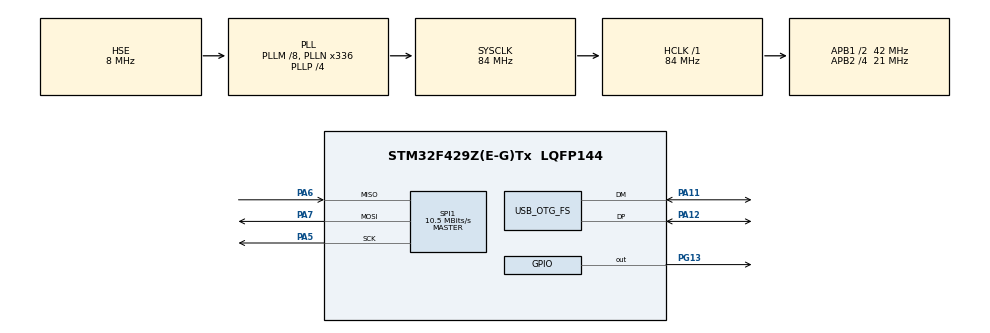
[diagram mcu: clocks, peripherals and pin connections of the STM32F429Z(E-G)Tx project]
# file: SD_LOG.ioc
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FATFS._MAX_SS=4096
FATFS._USE_LFN=1
Mcu.Family=STM32F4
Mcu.Name=STM32F429Z(E-G)Tx
Mcu.Package=LQFP144
NVIC.OTG_FS_IRQn=true\:0\:0\:false\:false\:true\:false\:true\:true
NVIC.PriorityGroup=NVIC_PRIORITYGROUP_4
PA11.Mode=Device_Only
PA11.Signal=USB_OTG_FS_DM
PA12.Mode=Device_Only
PA12.Signal=USB_OTG_FS_DP
PA5.Mode=Full_Duplex_Master
PA5.Signal=SPI1_SCK
PA6.Mode=Full_Duplex_Master
PA6.Signal=SPI1_MISO
PA7.Mode=Full_Duplex_Master
PA7.Signal=SPI1_MOSI
PG13.Signal=GPIO_Output
PH0/OSC_IN.Mode=HSE-External-Oscillator
PH0/OSC_IN.Signal=RCC_OSC_IN
PH1/OSC_OUT.Mode=HSE-External-Oscillator
PH1/OSC_OUT.Signal=RCC_OSC_OUT
ProjectManager.HeapSize=0x200
ProjectManager.StackSize=0x400
ProjectManager.TargetToolchain=STM32CubeIDE
RCC.48MHZClocksFreq_Value=48000000
RCC.AHBFreq_Value=84000000
RCC.APB1CLKDivider=RCC_HCLK_DIV2
RCC.APB1Freq_Value=42000000
RCC.APB1TimFreq_Value=84000000
RCC.APB2CLKDivider=RCC_HCLK_DIV4
RCC.APB2Freq_Value=21000000
RCC.APB2TimFreq_Value=42000000
RCC.CortexFreq_Value=84000000
RCC.HCLKFreq_Value=84000000
RCC.HSE_VALUE=8000000
RCC.HSI_VALUE=16000000
RCC.LSE_VALUE=32768
RCC.PLLM=8
RCC.PLLN=336
RCC.PLLP=RCC_PLLP_DIV4
RCC.PLLQ=7
RCC.SYSCLKFreq_VALUE=84000000
RCC.SYSCLKSource=RCC_SYSCLKSOURCE_PLLCLK
RCC.VCOOutputFreq_Value=336000000
SPI1.CalculateBaudRate=10.5 MBits/s
SPI1.Direction=SPI_DIRECTION_2LINES
SPI1.Mode=SPI_MODE_MASTER
SPI1.VirtualType=VM_MASTER
USB_DEVICE.CLASS_NAME_FS=CDC
USB_DEVICE.VirtualMode-CDC_FS=Cdc
USB_DEVICE.VirtualModeFS=Cdc_FS
USB_OTG_FS.VirtualMode=Device_Only
VP_FATFS_VS_Generic.Mode=User_defined
VP_USB_DEVICE_VS_USB_DEVICE_CDC_FS.Mode=CDC_FS
board=custom

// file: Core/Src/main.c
/* USER CODE BEGIN Header */
/**
  ******************************************************************************
  * @file           : main.c
  * @brief          : Main program body
  ******************************************************************************
  * @attention
  *
  * Copyright (c) 2025 STMicroelectronics.
  * All rights reserved.
  *
  * This software is licensed under terms that can be found in the LICENSE file
  * in the root directory of this software component.
  * If no LICENSE file comes with this software, it is provided AS-IS.
  *
  ******************************************************************************
  */
/* USER CODE END Header */
#include "main.h"
#include "fatfs.h"
#include "usb_device.h"

/* USER CODE BEGIN Includes */
#include <stdbool.h>
#include <stdio.h>
#include <string.h>
/* USER CODE END Includes */

/* USER CODE BEGIN PV */
SPI_HandleTypeDef hspi1;
char TxBuffer[250];
/* USER CODE END PV */

void SystemClock_Config(void);
static void MX_GPIO_Init(void);
static void MX_SPI1_Init(void);
/* USER CODE BEGIN PFP */
void MX_USB_DEVICE_Init(void);  // ✅ ADDED: USB Device initialization
static void SD_Card_Test(void);
/* USER CODE END PFP */

/* USER CODE BEGIN 0 */
static void USB_CDC_Print(char* str)
{
    CDC_Transmit_FS((uint8_t*)str, strlen(str));  // Send via USB CDC
    HAL_Delay(10);  // Small delay to ensure transmission completes
}
/* USER CODE END 0 */

int main(void)
{

  /* MCU Configuration--------------------------------------------------------*/

  /* Reset of all peripherals, Initializes the Flash interface and the Systick. */
  HAL_Init();

  /* Configure the system clock */
  SystemClock_Config();

  /* Initialize all configured peripherals */
  MX_GPIO_Init();
  MX_USB_DEVICE_Init();
  MX_SPI1_Init();

  /* USER CODE BEGIN 2 */
  MX_FATFS_Init();
  HAL_Delay(2000);  // ✅ ADDED: Wait for USB enumeration to complete
  USB_CDC_Print("\r\n=== STM32F429 SD Card Test via USB CDC ===\r\n\n");  // ✅ CHANGED
  SD_Card_Test();
  /* USER CODE END 2 */

  /* Infinite loop */
  while (1)
  {

  }
}

static void SD_Card_Test(void)
{
  FATFS FatFs;
  FIL Fil;
  FRESULT FR_Status;
  FATFS *FS_Ptr;
  UINT RWC, WWC; // Read/Write Word Counter
  DWORD FreeClusters;
  uint32_t TotalSize, FreeSpace;
  char RW_Buffer[200];

  do
  {
    //------------------[ Mount The SD Card ]--------------------
    FR_Status = f_mount(&FatFs, "", 1);
    if (FR_Status != FR_OK)
    {
      sprintf(TxBuffer, "Error! While Mounting SD Card, Error Code: (%i)\r\n", FR_Status);
      USB_CDC_Print(TxBuffer);  // ✅ CHANGED: UART_Print → USB_CDC_Print
      break;
    }
    sprintf(TxBuffer, "SD Card Mounted Successfully! \r\n\n");
    USB_CDC_Print(TxBuffer);  // ✅ CHANGED

    //------------------[ Get & Print The SD Card Size & Free Space ]--------------------
    f_getfree("", &FreeClusters, &FS_Ptr);
    TotalSize = (uint32_t)((FS_Ptr->n_fatent - 2) * FS_Ptr->csize * 0.5);
    FreeSpace = (uint32_t)(FreeClusters * FS_Ptr->csize * 0.5);
    sprintf(TxBuffer, "Total SD Card Size: %lu Bytes\r\n", TotalSize);
    USB_CDC_Print(TxBuffer);  // ✅ CHANGED
    sprintf(TxBuffer, "Free SD Card Space: %lu Bytes\r\n\n", FreeSpace);
    USB_CDC_Print(TxBuffer);  // ✅ CHANGED

    //------------------[ Open A Text File For Write & Write Data ]--------------------
    //Open the file
    FR_Status = f_open(&Fil, "TextFileWrite.txt", FA_WRITE | FA_READ | FA_CREATE_ALWAYS);
    if(FR_Status != FR_OK)
    {
      sprintf(TxBuffer, "Error! While Creating/Opening A New Text File, Error Code: (%i)\r\n", FR_Status);
      USB_CDC_Print(TxBuffer);  // ✅ CHANGED
      break;
    }
    sprintf(TxBuffer, "Text File Created & Opened! Writing Data To The Text File..\r\n\n");
    USB_CDC_Print(TxBuffer);

    // (1) Write Data To The Text File [ Using f_puts() Function ]
    f_puts("Hello! From STM32F429 To SD Card Over SPI1, Using f_puts()\n", &Fil);
    strcpy(RW_Buffer, "Hello! From STM32F429 To SD Card Over SPI1, Using f_write()\r\n");
    f_write(&Fil, RW_Buffer, strlen(RW_Buffer), &WWC);
    // Close The File
    f_close(&Fil);

    //------------------[ Open A Text File For Read & Read Its Data ]--------------------
    // Open The File
    FR_Status = f_open(&Fil, "TextFileWrite.txt", FA_READ);
    if(FR_Status != FR_OK)
    {
      sprintf(TxBuffer, "Error! While Opening (TextFileWrite.txt) File For Read.. \r\n");
      USB_CDC_Print(TxBuffer);  // ✅ CHANGED
      break;
    }

    // (1) Read The Text File's Data [ Using f_gets() Function ]
    f_gets(RW_Buffer, sizeof(RW_Buffer), &Fil);
    sprintf(TxBuffer, "Data Read From (TextFileWrite.txt) Using f_gets():%s", RW_Buffer);
    USB_CDC_Print(TxBuffer);  // ✅ CHANGED

    // (2) Read The Text File's Data [ Using f_read() Function ]
    f_read(&Fil, RW_Buffer, f_size(&Fil), &RWC);
    sprintf(TxBuffer, "Data Read From (TextFileWrite.txt) Using f_read():%s", RW_Buffer);
    USB_CDC_Print(TxBuffer);  // ✅ CHANGED

    // Close The File
    f_close(&Fil);
    sprintf(TxBuffer, "File Closed! \r\n\n");
    USB_CDC_Print(TxBuffer);  // ✅ CHANGED

    //------------------[ Open An Existing Text File, Update Its Content, Read It Back ]--------------------
    // (1) Open The Existing File For Write (Update)
    FR_Status = f_open(&Fil, "TextFileWrite.txt", FA_OPEN_EXISTING | FA_WRITE);
    FR_Status = f_lseek(&Fil, f_size(&Fil)); // Move The File Pointer To The EOF (End-Of-File)
    if(FR_Status != FR_OK)
    {
      sprintf(TxBuffer, "Error! While Opening (TextFileWrite.txt) File For Update.. \r\n");
      USB_CDC_Print(TxBuffer);  // ✅ CHANGED
      break;
    }

    // (2) Write New Line of Text Data To The File
    FR_Status = f_puts("This New Line Was Added During Update!\r\n", &Fil);
    f_close(&Fil);
    memset(RW_Buffer,'\0',sizeof(RW_Buffer)); // Clear The Buffer

    // (3) Read The Contents of The Text File After The Update
    FR_Status = f_open(&Fil, "TextFileWrite.txt", FA_READ); // Open The File For Read
    f_read(&Fil, RW_Buffer, f_size(&Fil), &RWC);
    sprintf(TxBuffer, "Data Read From (TextFileWrite.txt) After Update:%s", RW_Buffer);
    USB_CDC_Print(TxBuffer);  // ✅ CHANGED
    f_close(&Fil);

    //------------------[ Delete The Text File ]--------------------
    // Delete The File
    /*
    FR_Status = f_unlink("TextFileWrite.txt");
    if (FR_Status != FR_OK){
        sprintf(TxBuffer, "Error! While Deleting The (TextFileWrite.txt) File.. \r\n");
        USB_CDC_Print(TxBuffer);
    }
    */
  } while(0);

  //------------------[ Test Complete! Unmount The SD Card ]--------------------
  FR_Status = f_mount(NULL, "", 0);
  if (FR_Status != FR_OK)
  {
      sprintf(TxBuffer, "Error! While Un-mounting SD Card, Error Code: (%i)\r\n", FR_Status);
      USB_CDC_Print(TxBuffer);  // ✅ CHANGED
  } else {
      sprintf(TxBuffer, "SD Card Un-mounted Successfully! \r\n");
      USB_CDC_Print(TxBuffer);  // ✅ CHANGED
  }
}

void SystemClock_Config(void)
{
  RCC_OscInitTypeDef RCC_OscInitStruct = {0};
  RCC_ClkInitTypeDef RCC_ClkInitStruct = {0};

  /** Configure the main internal regulator output voltage
  */
  __HAL_RCC_PWR_CLK_ENABLE();
  __HAL_PWR_VOLTAGESCALING_CONFIG(PWR_REGULATOR_VOLTAGE_SCALE3);

  /** Initializes the RCC Oscillators according to the specified parameters
  * in the RCC_OscInitTypeDef structure.
  */
  RCC_OscInitStruct.OscillatorType = RCC_OSCILLATORTYPE_HSE;
  RCC_OscInitStruct.HSEState = RCC_HSE_ON;
  RCC_OscInitStruct.PLL.PLLState = RCC_PLL_ON;
  RCC_OscInitStruct.PLL.PLLSource = RCC_PLLSOURCE_HSE;
  RCC_OscInitStruct.PLL.PLLM = 8;
  RCC_OscInitStruct.PLL.PLLN = 336;
  RCC_OscInitStruct.PLL.PLLP = RCC_PLLP_DIV4;
  RCC_OscInitStruct.PLL.PLLQ = 7;
  if (HAL_RCC_OscConfig(&RCC_OscInitStruct) != HAL_OK)
  {
    Error_Handler();
  }

  /** Initializes the CPU, AHB and APB buses clocks
  */
  RCC_ClkInitStruct.ClockType = RCC_CLOCKTYPE_HCLK|RCC_CLOCKTYPE_SYSCLK
                              |RCC_CLOCKTYPE_PCLK1|RCC_CLOCKTYPE_PCLK2;
  RCC_ClkInitStruct.SYSCLKSource = RCC_SYSCLKSOURCE_PLLCLK;
  RCC_ClkInitStruct.AHBCLKDivider = RCC_SYSCLK_DIV1;
  RCC_ClkInitStruct.APB1CLKDivider = RCC_HCLK_DIV2;
  RCC_ClkInitStruct.APB2CLKDivider = RCC_HCLK_DIV4;

  if (HAL_RCC_ClockConfig(&RCC_ClkInitStruct, FLASH_LATENCY_2) != HAL_OK)
  {
    Error_Handler();
  }
}

static void MX_SPI1_Init(void)
{

  /* SPI1 parameter configuration*/
  hspi1.Instance = SPI1;
  hspi1.Init.Mode = SPI_MODE_MASTER;
  hspi1.Init.Direction = SPI_DIRECTION_2LINES;
  hspi1.Init.DataSize = SPI_DATASIZE_8BIT;
  hspi1.Init.CLKPolarity = SPI_POLARITY_LOW;
  hspi1.Init.CLKPhase = SPI_PHASE_1EDGE;
  hspi1.Init.NSS = SPI_NSS_SOFT;
  hspi1.Init.BaudRatePrescaler = SPI_BAUDRATEPRESCALER_256;
  hspi1.Init.FirstBit = SPI_FIRSTBIT_MSB;
  hspi1.Init.TIMode = SPI_TIMODE_DISABLE;
  hspi1.Init.CRCCalculation = SPI_CRCCALCULATION_DISABLE;
  hspi1.Init.CRCPolynomial = 10;
  if (HAL_SPI_Init(&hspi1) != HAL_OK)
  {
    Error_Handler();
  }

}

static void MX_GPIO_Init(void)
{
  GPIO_InitTypeDef GPIO_InitStruct = {0};

  /* GPIO Ports Clock Enable */
  __HAL_RCC_GPIOH_CLK_ENABLE();
  __HAL_RCC_GPIOA_CLK_ENABLE();
  __HAL_RCC_GPIOG_CLK_ENABLE();

  /*Configure GPIO pin Output Level */
  HAL_GPIO_WritePin(GPIOG, GPIO_PIN_13, GPIO_PIN_RESET);

  /*Configure GPIO pin : PG13 */
  GPIO_InitStruct.Pin = GPIO_PIN_13;
  GPIO_InitStruct.Mode = GPIO_MODE_OUTPUT_PP;
  GPIO_InitStruct.Pull = GPIO_NOPULL;
  GPIO_InitStruct.Speed = GPIO_SPEED_FREQ_VERY_HIGH;
  HAL_GPIO_Init(GPIOG, &GPIO_InitStruct);

}

void Error_Handler(void)
{
  __disable_irq();
  while (1)
  {
  }
}
